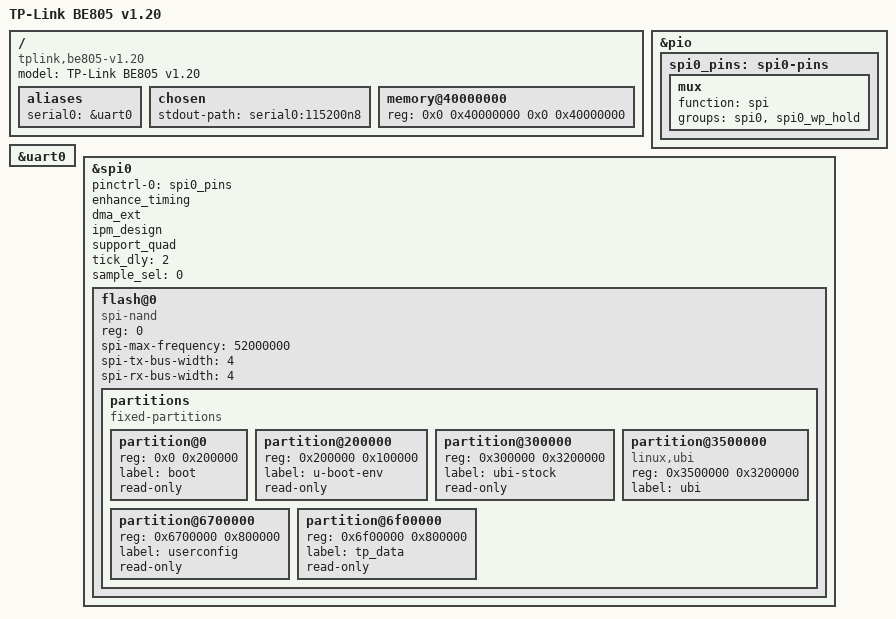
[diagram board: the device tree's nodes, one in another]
// SPDX-License-Identifier: GPL-2.0-or-later OR MIT
// Author: Yanase Yuki <dev@zpc.st>
/dts-v1/;
#include "mt7988.dtsi"

/ {
	compatible = "tplink,be805-v1.20", "mediatek,mt7988a";
	model = "TP-Link BE805 v1.20";

	aliases {
		serial0 = &uart0;
	};

	chosen {
		stdout-path = "serial0:115200n8";
	};

	memory@40000000 {
		device_type = "memory";
		reg = <0x0 0x40000000 0x0 0x40000000>;
	};
};

&pio {
	spi0_pins: spi0-pins {
		mux {
			function = "spi";
			groups = "spi0", "spi0_wp_hold";
		};
	};
};

&uart0 {
	status = "okay";
};

&spi0 {
	status = "okay";
	pinctrl-names = "default";
	pinctrl-0 = <&spi0_pins>;
	#address-cells = <1>;
	#size-cells = <0>;

	enhance_timing;
	dma_ext;
	ipm_design;
	support_quad;
	tick_dly = <2>;
	sample_sel = <0>;

	flash@0 {
		compatible = "spi-nand";
		reg = <0>;

		spi-max-frequency = <52000000>;
		spi-tx-bus-width = <4>;
		spi-rx-bus-width = <4>;

		partitions {
			compatible = "fixed-partitions";
			#address-cells = <1>;
			#size-cells = <1>;

			partition@0 {
				reg = <0x0 0x200000>;
				label = "boot";
				read-only;
			};

			partition@200000 {
				reg = <0x200000 0x100000>;
				label = "u-boot-env";
				read-only;
			};

			partition@300000 {
				reg = <0x300000 0x3200000>;
				label = "ubi-stock";
				read-only;
			};

			partition@3500000 {
				compatible = "linux,ubi";
				reg = <0x3500000 0x3200000>;
				label = "ubi";
			};

			partition@6700000 {
				reg = <0x6700000 0x800000>;
				label = "userconfig";
				read-only;
			};

			partition@6f00000 {
				reg = <0x6f00000 0x800000>;
				label = "tp_data";
				read-only;
			};
		};
	};
};

